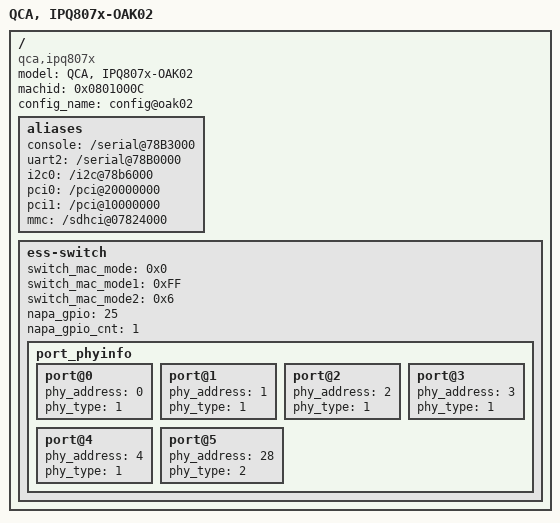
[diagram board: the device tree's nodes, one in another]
/*
 * Copyright (c) 2016 - 2018, The Linux Foundation. All rights reserved.
 *
 * This program is free software; you can redistribute it and/or modify
 * it under the terms of the GNU General Public License version 2 and
 * only version 2 as published by the Free Software Foundation.
 *
 * This program is distributed in the hope that it will be useful,
 * but WITHOUT ANY WARRANTY; without even the implied warranty of
 * MERCHANTABILITY or FITNESS FOR A PARTICULAR PURPOSE.  See the
 * GNU General Public License for more details.
 */

/dts-v1/;
#include "hw29765589p0p512p1024p4x4p8x8-soc.dtsi"
#include <dt-bindings/qcom/gpio-hw29765589p0p512p1024p4x4p8x8.h>
/ {
	model ="QCA, IPQ807x-OAK02";
	compatible = "qca,ipq807x", "qca,ipq807x-oak02";
	machid = <0x0801000C>;
	config_name = "config@oak02";

	aliases {
		console = "/serial@78B3000";
		uart2 = "/serial@78B0000";
		i2c0 = "/i2c@78b6000";
		pci0 = "/pci@20000000";
		pci1 = "/pci@10000000";
		mmc = "/sdhci@07824000";
	};
	ess-switch {
		switch_mac_mode = <0x0>;
		switch_mac_mode1 = <0xFF>;
		switch_mac_mode2 = <0x6>;
		napa_gpio = <25>;    /*Napa reset , demo board was gpio44,ax3 was gpio 25*/
		napa_gpio_cnt = <1>;
				port_phyinfo {
			port@0 {
				phy_address = <0>;
				phy_type = <1>;
			};
			port@1 {
				phy_address = <1>;
				phy_type = <1>;
			};
			port@2 {
				phy_address = <2>;
				phy_type = <1>;
			};
			port@3 {
				phy_address = <3>;
				phy_type = <1>;
			};
			port@4 {
				phy_address = <4>;
				phy_type = <1>;
			};
			port@5 {
				phy_address = <28>;
				phy_type = <2>;
			};
		};
		
		

	};

};

